# cslr_intc register map
Vendor: Texas Instruments
Peripheral module from a debugger description file (folder TCI6484_C6457).
Registers are 32-bit, read-only, reset 0x0 unless marked. A register's access mark holds for its fields unless they carry their own. Offsets are as the file gives them; lines under a group give offsets from that group; [hi:lo] are bit positions; {n}, {i} and the like mark numbered series; 'fields as' and 'values as' point back to an identical list; <NAME> marks a mode.

## INTC — Interrupt
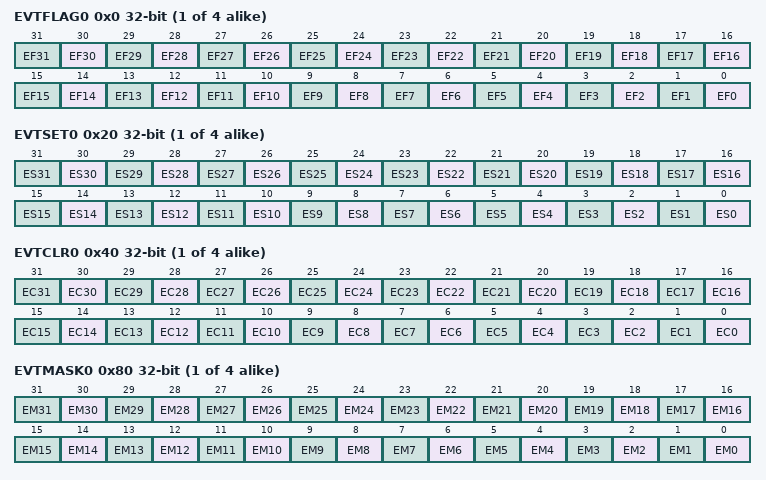
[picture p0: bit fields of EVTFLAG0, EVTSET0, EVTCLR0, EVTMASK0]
{0x0+4i} EVTFLAG{i} (i=0..3) — Event Flag 0-3 Register - Events Status 0-31
  [n] EF{n} (n=0..31) — Event Flag number {n}
{0x20+4i} EVTSET{i} wo (i=0..3) — Event Set 0-3 Register - Used to Sets Events 0-127
  [n] ES{n} (n=0..31) — Event Set number {n}
{0x40+4i} EVTCLR{i} wo (i=0..3) — Event Clr 0-3 Register - Used to Clear Events 0-127
  [n] EC{n} (n=0..31) — Event Clear {n}
{0x80+4i} EVTMASK{i} rw (i=0..3) — Event Mask 0-3 Register - Used to Mask Events 0-127
  [n] EM{n} (n=0..31) — Event Mask {n}
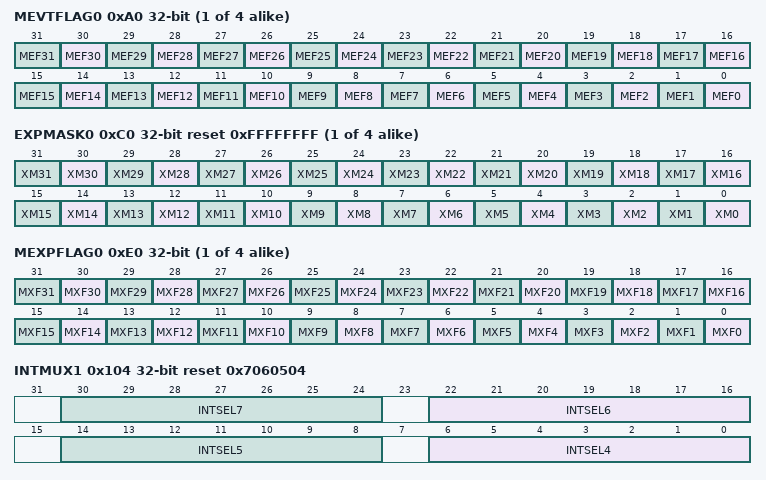
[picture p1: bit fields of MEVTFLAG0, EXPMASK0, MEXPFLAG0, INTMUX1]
{0xA0+4i} MEVTFLAG{i} (i=0..3) — Event Mask Flag 0-3 Register - Status Flags of Masked Events 0-127
  [n] MEF{n} (n=0..31) — Masked Event Status {n}
{0xC0+4i} EXPMASK{i} rw reset 0xFFFFFFFF (i=0..3) — Exception Mask 0-3 Register - Mask to generate EXCEP upon Events 0-127
  [n] XM{n} (n=0..31) — Exception Mask {n}
{0xE0+4i} MEXPFLAG{i} (i=0..3) — Masked Exceptions Flag 1 Register - Status Flags of Masked Exception Events 32-63
  [n] MXF{n} (n=0..31) — Masked Event Flag {n}
0x104 INTMUX1 access not given reset 0x7060504 — Interrupt Multiplexer Register 1
  [8n-26:8n-32] INTSEL{n} rw (n=4..7) — Interrupt Selector {n}
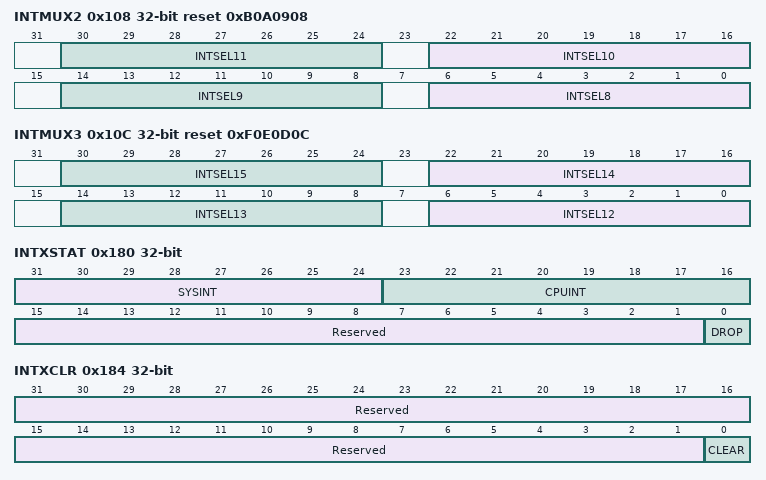
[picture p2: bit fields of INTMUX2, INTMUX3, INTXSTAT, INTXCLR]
0x108 INTMUX2 access not given reset 0xB0A0908 — Interrupt Multiplexer Register 2
  [8n-58:8n-64] INTSEL{n} rw (n=8..11) — Interrupt Selector {n}
0x10C INTMUX3 access not given reset 0xF0E0D0C — Interrupt Multiplexer Register 3
  [8n-90:8n-96] INTSEL{n} rw (n=12..15) — Interrupt Selector {n}
0x180 INTXSTAT access not given — Interrupt Exception Status Register - Holds ID of CPU Int and System Even number of the dropped Event
  [31:24] SYSINT ro — System Event Number
  [23:16] CPUINT ro — CPU Interrupt Number for Exception
    {v}=NUM{v} (CPU Interrupt Number {v}) (v=0..9); {v}=NUM{v-6} (CPU Interrupt Number {v-6}) (v=16..21)
  [15:1] Reserved — (access N)
  [0] DROP ro — Dropped Event Flag
    0=NO (No Events Dropped); 1=YES (Event was dropped by the CPU)
0x184 INTXCLR access not given — Interrupt Exception Clear Register - Clears Interrupt Exception Status Register
  [31:1] Reserved — (access N)
  [0] CLEAR wo — Interrupt Exception Clear Field
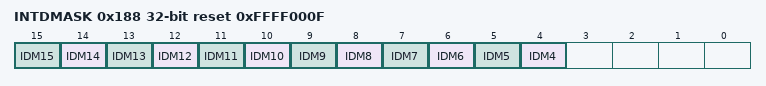
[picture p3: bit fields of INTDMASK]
0x188 INTDMASK access not given reset 0xFFFF000F — Dropped Interrupt Mask Register
  [all] fields
    1=IGNORED
  [n] IDM{n} rw (n=4..15) — Interrupt Drop Mask {n}
